# CY8C5888LTI_LP097 register map
File version: 0.1
CY8C58LP
Registers are 8-bit, read-write, no defined reset value unless marked. A register's access mark holds for its fields unless they carry their own. Offsets are from the block's base; lines under a group give offsets from that group; [hi:lo] are bit positions; {n}, {i} and the like mark numbered series; 'fields as' and 'values as' point back to an identical list; <NAME> marks a mode.

## Memory map
0x00000000 UART_5 — UART
0x00000000 UART_6 — UART
0x00000000 UART_7 — UART
0x00000000 UART_2 — UART
0x00000000 UART_1 — UART
0x00000000 UART_4 — UART
0x00000000 UART_3 — UART

## UART_5 — UART
Base 0x00000000
0x40006422 RX_UART_5_RX_ADDRESS1 — RX Address1 Register
0x40006432 RX_UART_5_RX_ADDRESS2 — RX Address2 Register
0x40006442 RX_UART_5_RX_DATA — RX Data Register
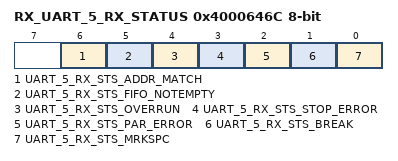
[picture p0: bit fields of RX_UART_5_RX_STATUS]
0x4000646C RX_UART_5_RX_STATUS — RX status register
  [6] UART_5_RX_STS_ADDR_MATCH ro, [5] UART_5_RX_STS_FIFO_NOTEMPTY ro, [4] UART_5_RX_STS_OVERRUN ro, [3] UART_5_RX_STS_STOP_ERROR ro, [2] UART_5_RX_STS_PAR_ERROR ro, [1] UART_5_RX_STS_BREAK ro, [0] UART_5_RX_STS_MRKSPC ro

## UART_6 — UART
Base 0x00000000
0x40006424 RX_UART_6_RX_ADDRESS1 — RX Address1 Register
0x40006434 RX_UART_6_RX_ADDRESS2 — RX Address2 Register
0x40006444 RX_UART_6_RX_DATA — RX Data Register
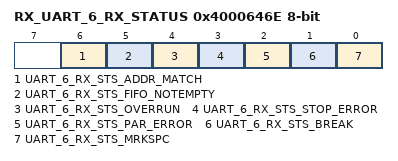
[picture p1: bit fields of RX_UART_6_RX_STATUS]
0x4000646E RX_UART_6_RX_STATUS — RX status register
  [6] UART_6_RX_STS_ADDR_MATCH ro, [5] UART_6_RX_STS_FIFO_NOTEMPTY ro, [4] UART_6_RX_STS_OVERRUN ro, [3] UART_6_RX_STS_STOP_ERROR ro, [2] UART_6_RX_STS_PAR_ERROR ro, [1] UART_6_RX_STS_BREAK ro, [0] UART_6_RX_STS_MRKSPC ro

## UART_7 — UART
Base 0x00000000
0x40006420 RX_UART_7_RX_ADDRESS1 — RX Address1 Register
0x40006430 RX_UART_7_RX_ADDRESS2 — RX Address2 Register
0x40006440 RX_UART_7_RX_DATA — RX Data Register
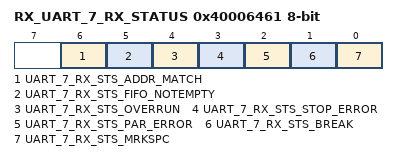
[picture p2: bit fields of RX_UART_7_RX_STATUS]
0x40006461 RX_UART_7_RX_STATUS — RX status register
  [6] UART_7_RX_STS_ADDR_MATCH ro, [5] UART_7_RX_STS_FIFO_NOTEMPTY ro, [4] UART_7_RX_STS_OVERRUN ro, [3] UART_7_RX_STS_STOP_ERROR ro, [2] UART_7_RX_STS_PAR_ERROR ro, [1] UART_7_RX_STS_BREAK ro, [0] UART_7_RX_STS_MRKSPC ro

## UART_2 — UART
Base 0x00000000
0x40006525 RX_UART_2_RX_ADDRESS1 — RX Address1 Register
0x40006535 RX_UART_2_RX_ADDRESS2 — RX Address2 Register
0x40006545 RX_UART_2_RX_DATA — RX Data Register
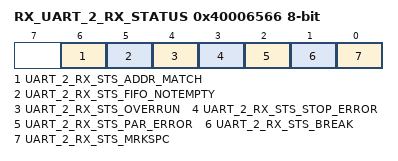
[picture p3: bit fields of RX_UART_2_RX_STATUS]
0x40006566 RX_UART_2_RX_STATUS — RX status register
  [6] UART_2_RX_STS_ADDR_MATCH ro, [5] UART_2_RX_STS_FIFO_NOTEMPTY ro, [4] UART_2_RX_STS_OVERRUN ro, [3] UART_2_RX_STS_STOP_ERROR ro, [2] UART_2_RX_STS_PAR_ERROR ro, [1] UART_2_RX_STS_BREAK ro, [0] UART_2_RX_STS_MRKSPC ro

## UART_1 — UART
Base 0x00000000
0x4000644A TX_UART_1_TX_DATA — TX Data Register
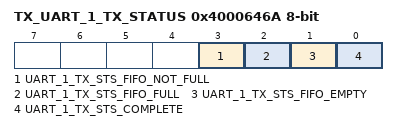
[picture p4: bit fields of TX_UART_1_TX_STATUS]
0x4000646A TX_UART_1_TX_STATUS — TX status register
  [3] UART_1_TX_STS_FIFO_NOT_FULL ro, [2] UART_1_TX_STS_FIFO_FULL ro, [1] UART_1_TX_STS_FIFO_EMPTY ro, [0] UART_1_TX_STS_COMPLETE ro

## UART_4 — UART
Base 0x00000000
0x40006427 RX_UART_4_RX_ADDRESS1 — RX Address1 Register
0x40006437 RX_UART_4_RX_ADDRESS2 — RX Address2 Register
0x40006447 RX_UART_4_RX_DATA — RX Data Register
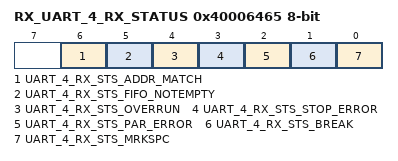
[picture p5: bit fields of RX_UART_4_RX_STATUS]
0x40006465 RX_UART_4_RX_STATUS — RX status register
  [6] UART_4_RX_STS_ADDR_MATCH ro, [5] UART_4_RX_STS_FIFO_NOTEMPTY ro, [4] UART_4_RX_STS_OVERRUN ro, [3] UART_4_RX_STS_STOP_ERROR ro, [2] UART_4_RX_STS_PAR_ERROR ro, [1] UART_4_RX_STS_BREAK ro, [0] UART_4_RX_STS_MRKSPC ro

## UART_3 — UART
Base 0x00000000
0x4000642F RX_UART_3_RX_ADDRESS1 — RX Address1 Register
0x4000643F RX_UART_3_RX_ADDRESS2 — RX Address2 Register
0x4000644F RX_UART_3_RX_DATA — RX Data Register
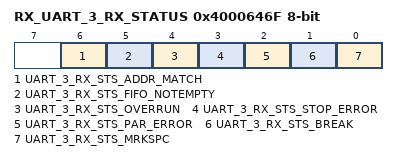
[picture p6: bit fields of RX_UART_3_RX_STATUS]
0x4000646F RX_UART_3_RX_STATUS — RX status register
  [6] UART_3_RX_STS_ADDR_MATCH ro, [5] UART_3_RX_STS_FIFO_NOTEMPTY ro, [4] UART_3_RX_STS_OVERRUN ro, [3] UART_3_RX_STS_STOP_ERROR ro, [2] UART_3_RX_STS_PAR_ERROR ro, [1] UART_3_RX_STS_BREAK ro, [0] UART_3_RX_STS_MRKSPC ro
